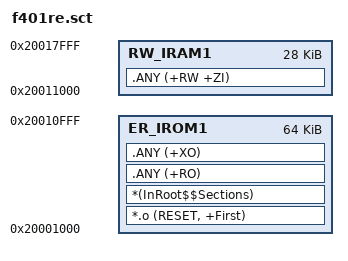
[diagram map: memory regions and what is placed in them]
; *************************************************************
; *** Scatter-Loading Description File generated by uVision ***
; *************************************************************

LR_IROM1 0x20001000 0x00010000  {    ; load region size_region
  ER_IROM1 0x20001000 0x00010000  {  ; load address = execution address
   *.o (RESET, +First)
   *(InRoot$$Sections)
   .ANY (+RO)
   .ANY (+XO)
  }
  RW_IRAM1 0x20011000 0x00007000  {  ; RW data
   .ANY (+RW +ZI)
  }
}

